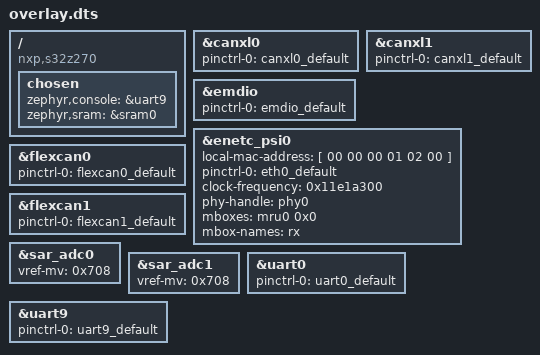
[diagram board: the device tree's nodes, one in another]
/ {
	compatible = "nxp,s32z270";
	chosen {
		zephyr,console = &uart9;
		zephyr,sram = &sram0;
	};
};
&canxl0{
	status = "okay";
	pinctrl-0 = < &canxl0_default >;
	pinctrl-names = "default";
};
&canxl1{
	pinctrl-0 = < &canxl1_default >;
	pinctrl-names = "default";
};
&emdio{
	status = "okay";
	pinctrl-0 = < &emdio_default >;
	pinctrl-names = "default";
};
&enetc_psi0{
	status = "okay";
	local-mac-address = [ 00 00 00 01 02 00 ];
	pinctrl-0 = < &eth0_default >;
	pinctrl-names = "default";
	clock-frequency = < 0x11e1a300 >;
	phy-handle = < &phy0 >;
	mboxes = < &mru0 0x0 >;
	mbox-names = "rx";
};
&flexcan0{
	pinctrl-0 = < &flexcan0_default >;
	pinctrl-names = "default";
};
&flexcan1{
	pinctrl-0 = < &flexcan1_default >;
	pinctrl-names = "default";
};
&sar_adc0{
	vref-mv = < 0x708 >;
};
&sar_adc1{
	vref-mv = < 0x708 >;
};
&uart0{
	status = "okay";
	pinctrl-0 = < &uart0_default >;
	pinctrl-names = "default";
};
&uart9{
	status = "okay";
	pinctrl-0 = < &uart9_default >;
	pinctrl-names = "default";
};
